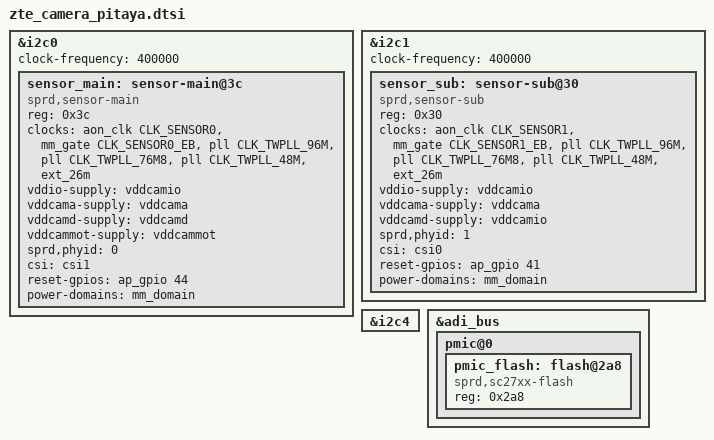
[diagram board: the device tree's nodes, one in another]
&i2c0 {
	status = "okay";
	clock-frequency = <400000>;

	sensor_main: sensor-main@3c {
		compatible = "sprd,sensor-main";
		reg = <0x3c>;
		clock-names = "clk_src","sensor_eb",
			"clk_96m","clk_76m8",
			"clk_48m","clk_26m";
		clocks = <&aon_clk CLK_SENSOR0>, <&mm_gate CLK_SENSOR0_EB>,
			<&pll CLK_TWPLL_96M>,<&pll CLK_TWPLL_76M8>,
			<&pll CLK_TWPLL_48M>,<&ext_26m>;
		vddio-supply = <&vddcamio>;
		vddcama-supply = <&vddcama>;
		vddcamd-supply = <&vddcamd>;
		vddcammot-supply = <&vddcammot>;
		sprd,phyid = <0>;
		csi = <&csi1>;
		reset-gpios = <&ap_gpio 44 0>;
		//power-down-gpios = <&ap_gpio 46 0>;
		power-domains = <&mm_domain>;
	};
};

&i2c1 {
	status = "okay";
	clock-frequency = <400000>;

	sensor_sub: sensor-sub@30 {
		compatible = "sprd,sensor-sub";
		reg = <0x30>;
		clock-names = "clk_src","sensor_eb",
			"clk_96m","clk_76m8",
			"clk_48m","clk_26m";
		clocks = <&aon_clk CLK_SENSOR1>, <&mm_gate CLK_SENSOR1_EB>,
			<&pll CLK_TWPLL_96M>,<&pll CLK_TWPLL_76M8>,
			<&pll CLK_TWPLL_48M>,<&ext_26m>;
		vddio-supply = <&vddcamio>;
		vddcama-supply = <&vddcama>;
		vddcamd-supply = <&vddcamio>;
		sprd,phyid = <1>;
		csi = <&csi0>;
		reset-gpios = <&ap_gpio 41 0>;
		//power-down-gpios = <&ap_gpio 40 0>;
		power-domains = <&mm_domain>;
	};
};
&i2c4 {
	/delete-node/ flash-ic@63;
};

&adi_bus {
	pmic@0 {
		/delete-node/ flash@2a8;
	};
	pmic@0 {
		pmic_flash: flash@2a8 {
			compatible = "sprd,sc27xx-flash", "sprd,sc2721-flash";
			reg=<0x2a8>;
			status = "okay";
			};
		};
};



&pmic_flash {
	compatible = "sprd,sc27xx-flash", "sprd,sc2721-flash";
	reg=<0x2a8>;
};
